# VIM_VIM register map
Vendor: Texas Instruments
Peripheral module from a debugger description file (folder AM263).
Registers are 32-bit, access per field, reset 0x0 unless marked. A register's access mark holds for its fields unless they carry their own. Offsets are as the file gives them; lines under a group give offsets from that group; [hi:lo] are bit positions; {n}, {i} and the like mark numbered series; 'fields as' and 'values as' point back to an identical list; <NAME> marks a mode.

## VIM_VIM
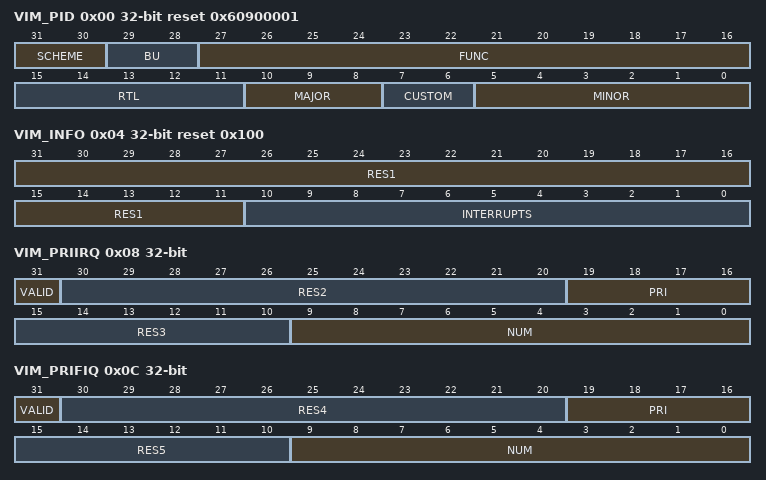
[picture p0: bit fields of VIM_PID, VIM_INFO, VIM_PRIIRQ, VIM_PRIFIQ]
0x00 VIM_PID ro reset 0x60900001
  [31:30] SCHEME — PID register scheme
  [29:28] BU — Business Unit: 10 = Processors
  [27:16] FUNC — Module ID
  [15:11] RTL — RTL revision. Will vary depending on release.
  [10:8] MAJOR — Major revision
  [7:6] CUSTOM
  [5:0] MINOR — Minor revision
0x04 VIM_INFO ro reset 0x100
  [31:11] RES1 — RESERVE FIELD
  [10:0] INTERRUPTS — Total number of Interrupts
0x08 VIM_PRIIRQ ro
  [31] VALID — Indicates that the num field is valid.
  [30:20] RES2 — RESERVE FIELD
  [19:16] PRI — Priority of the highest priority pending IRQ. valid only if the valid flag is set.
  [15:10] RES3 — RESERVE FIELD
  [9:0] NUM — Number of the highest priority pending IRQ. valid only if the valid flag is set.
0x0C VIM_PRIFIQ ro
  [31] VALID — Indicates that the num field is valid.
  [30:20] RES4 — RESERVE FIELD
  [19:16] PRI — Priority of the highest priority pending FIQ. valid only if the valid flag is set.
  [15:10] RES5 — RESERVE FIELD
  [9:0] NUM — Number of the highest priority pending FIQ. valid only if the valid flag is set.
0x10 VIM_IRQGSTS ro
  [31:0] STS — Indicates that the num field is valid.
0x14 VIM_FIQGSTS ro
  [31:0] STS — Indicates that the num field is valid.
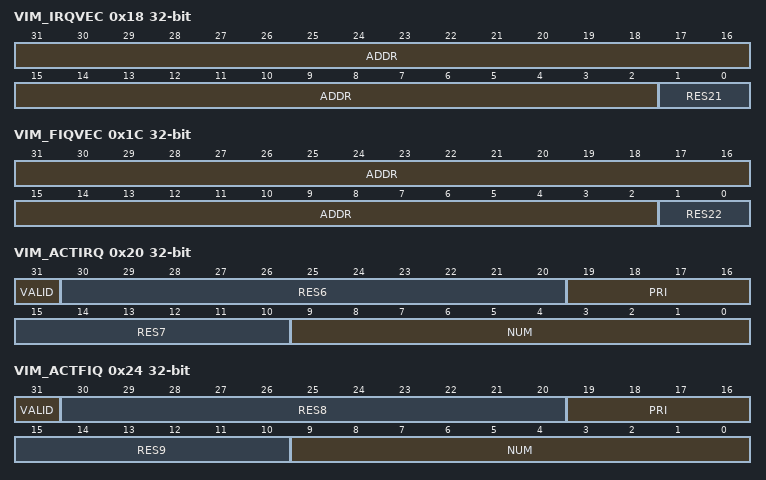
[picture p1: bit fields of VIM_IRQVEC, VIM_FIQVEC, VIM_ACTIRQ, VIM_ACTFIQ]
0x18 VIM_IRQVEC
  [31:2] ADDR rw — Upper 30 bits of the 32-bit vector address. Only valid if the Prioritized IRQ Register valid flag is true.
  [1:0] RES21 ro — RESERVE FIELD
0x1C VIM_FIQVEC
  [31:2] ADDR rw — Upper 30 bits of the 32-bit vector address. Only valid if the Prioritized FIQ Register valid flag is true.
  [1:0] RES22 ro — RESERVE FIELD
0x20 VIM_ACTIRQ ro
  [31] VALID — Indicates that the num field is valid. Set when the IRQ Vector Address Register is read and cleared whenever the IRQ Vector Address Register is written.
  [30:20] RES6 — RESERVE FIELD
  [19:16] PRI — Priority of the highest priority pending IRQ. valid only if the valid flag is set.
  [15:10] RES7 — RESERVE FIELD
  [9:0] NUM — Number of the currently active IRQ. Loaded from teh Prioritized IRQ Register whenever the IRQ Vector Address is read. Valid only if the valid flag is set.
0x24 VIM_ACTFIQ ro
  [31] VALID — Indicates that the num field is valid. Set when the FIQ Vector Address Register is read and cleared whenever the FIQ Vector Address Register is written.
  [30:20] RES8 — RESERVE FIELD
  [19:16] PRI — Priority of the highest priority pending IRQ. valid only if the valid flag is set.
  [15:10] RES9 — RESERVE FIELD
  [9:0] NUM — Number of the currently active FIQ. Loaded from teh Prioritized FIQ Register whenever the FIQ Vector Address is read. Valid only if the valid flag is set.
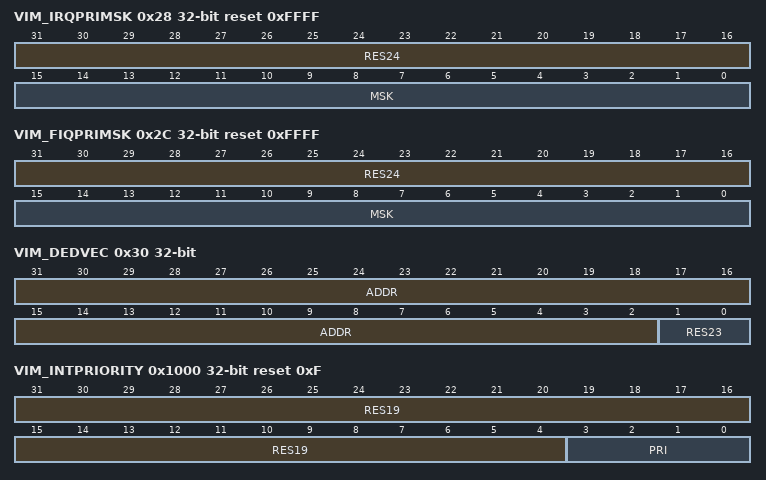
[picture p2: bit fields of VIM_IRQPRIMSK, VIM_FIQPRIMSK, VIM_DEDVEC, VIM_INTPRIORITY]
0x28 VIM_IRQPRIMSK reset 0xFFFF
  [31:16] RES24 ro — RESERVE FIELD
  [15:0] MSK rw — Each bit corresponds to the given priority. 1 - IRQs of this priority are enabled. 0 - IRQs of this priority are disabled.
0x2C VIM_FIQPRIMSK reset 0xFFFF
  [31:16] RES24 ro — RESERVE FIELD
  [15:0] MSK rw — Each bit corresponds to the given priority. 1 - FIQs of this priority are enabled. 0 - FIQs of this priority are disabled.
0x30 VIM_DEDVEC
  [31:2] ADDR rw — Upper 30 bits of the 32-bit vector address.
  [1:0] RES23 ro — RESERVE FIELD
0x400 VIM_RAW rw
  [31:0] STS — This is the raw status of the events in Group M Each bit corresponds to event Q where Q = Mx32+Bit Read 0 InactiveRead 1 Active/PendingWrite 0 No effectWrite 1 Set to Interrupt Raw Status
0x404 VIM_STS rw
  [31:0] MASK — This is the masked status of the events in Group M Each bit corresponds to event Q where Q = Mx32+Bit Read 0 Inactive or DisabledRead 1 Active/Pending and EnabledWrite 0 No effectWrite 1 Clear Interrupt Raw Status
0x408 VIM_INTR_EN_SET rw
  [31:0] MASK — This field is used to enable the mask of events in Group M Each bit corresponds to event Q where Q = Mx32+BitRead 0 DisabledRead 1 EnabledWrite 0 No effectWrite 1 Set Enable
0x40C VIM_INTER_EN_CLR rw
  [31:0] MASK — This field is used to disable the mask of events in Group M Each bit corresponds to event Q where Q = Mx32+BitRead 0 DisabledRead 1 EnabledWrite 0 No effectWrite 1 Clear Enable
0x410 VIM_IRQSTS rw
  [31:0] MASK — This is the masked status of the events in group M that are mapped to IRQ Each bit corresponds to event Q where Q = Mx32+BitRead 0 Inactive, Disabled, or not an IRQRead 1 Active/Pending, Enabled, and IRQWrite 0 No effectWrite 1 Clear Interrupt Raw Status (if IRQ)
0x414 VIM_FIQSTS rw
  [31:0] MASK — This is the masked status of the events in group M that are mapped to FIQ Each bit corresponds to event Q where Q = Mx32+BitRead 0 Inactive, Disabled, or not an FIQRead 1 Active/Pending, Enabled, and FIQWrite 0 No effectWrite 1 Clear Interrupt Raw Status (if FIQ)
0x418 VIM_INTMAP rw
  [31:0] MASK — This field is used to indicate which interrupt the corresponding event influences (if enabled) for event group M. Each bit corresponds to event Q where Q = Mx32+Bit 0 IRQ Interrupt (default)1 FIQ Interrupt
0x41C VIM_INTTYPE rw
  [31:0] VAL — This field is used to indicate whether the source of an interrupt is a level (default) or a pulse for event group M. This is informational so that an ISR may query this register and know whether it has to clear a pulse event or a level event (see 3.4 Interrupt Handling). The value has no effect on how the VIM hardware functions. The input interrupts are agnostic as to whether they are pulse or level. Each bit corresponds to event Q where Q = Mx32+Bit0 Level (default)1 Pulse
{0x400+0x20*i} VIM_RAW_{i} rw (i=1..7)
  fields as VIM_RAW
{0x404+0x20*i} VIM_STS_{i} rw (i=1..7)
  fields as VIM_STS
{0x408+0x20*i} VIM_INTR_EN_SET_{i} rw (i=1..7)
  fields as VIM_INTR_EN_SET
{0x40C+0x20*i} VIM_INTER_EN_CLR_{i} rw (i=1..7)
  fields as VIM_INTER_EN_CLR
{0x410+0x20*i} VIM_IRQSTS_{i} rw (i=1..7)
  fields as VIM_IRQSTS
{0x414+0x20*i} VIM_FIQSTS_{i} rw (i=1..7)
  fields as VIM_FIQSTS
{0x418+0x20*i} VIM_INTMAP_{i} rw (i=1..7)
  fields as VIM_INTMAP
{0x41C+0x20*i} VIM_INTTYPE_{i} rw (i=1..7)
  fields as VIM_INTTYPE
0x1000 VIM_INTPRIORITY reset 0xF
  [31:4] RES19 ro — RESERVE FIELD
  [3:0] PRI rw — This is the priority for interrupt Q. If two interrupts have the same priority, then whichever interrupt has the lower number Q wins arbitration 0 Highest Priority 15 Lowest Priority (Default)
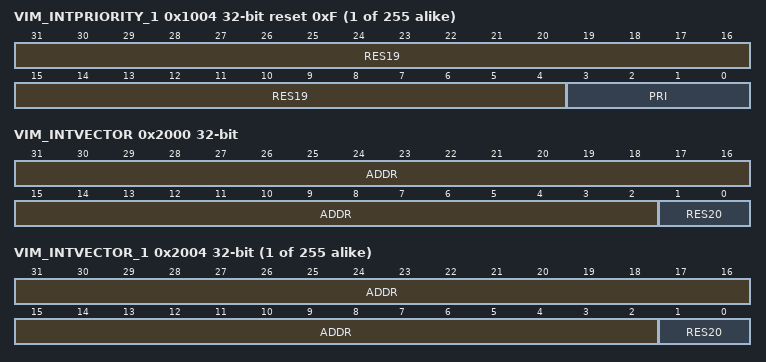
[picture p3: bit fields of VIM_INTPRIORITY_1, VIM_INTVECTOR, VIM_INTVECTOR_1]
{0x1000+4i} VIM_INTPRIORITY_{i} reset 0xF (i=1..255)
  fields as VIM_INTPRIORITY
0x2000 VIM_INTVECTOR
  [31:2] ADDR rw — This is the 32-bit Vector Address associated with interrupt Q. It is the address that will be reflected in the IRQ Vector Address (Base Address + 0x18) or FIQ Vector Address (Base Address + 0x1C) and the VECADDR pin when interrupt Q is the active interrupt.Internally, these values are kept in a RAM. The FIQ and IRQ state machines have priority access to this RAM. Writes to this register will be piped internally, but further writes to the MMR interface may be stalled until this write has a chance to complete in the RAM. The new Vector Address will not take effect until this write completes to the RAM. In order to tell if this write has completed, software may read this register back. That read will not be able to complete unless the write has landed.Reads to this register will stall the MMR interface until the read is able to be completed at the RAM.
  [1:0] RES20 ro — Reserved. Read as 0. The lower 2 bits of the 32-bit vector address are always 0. Vector addresses must be 32-bit aligned.
{0x2000+4i} VIM_INTVECTOR_{i} (i=1..255)
  fields as VIM_INTVECTOR
